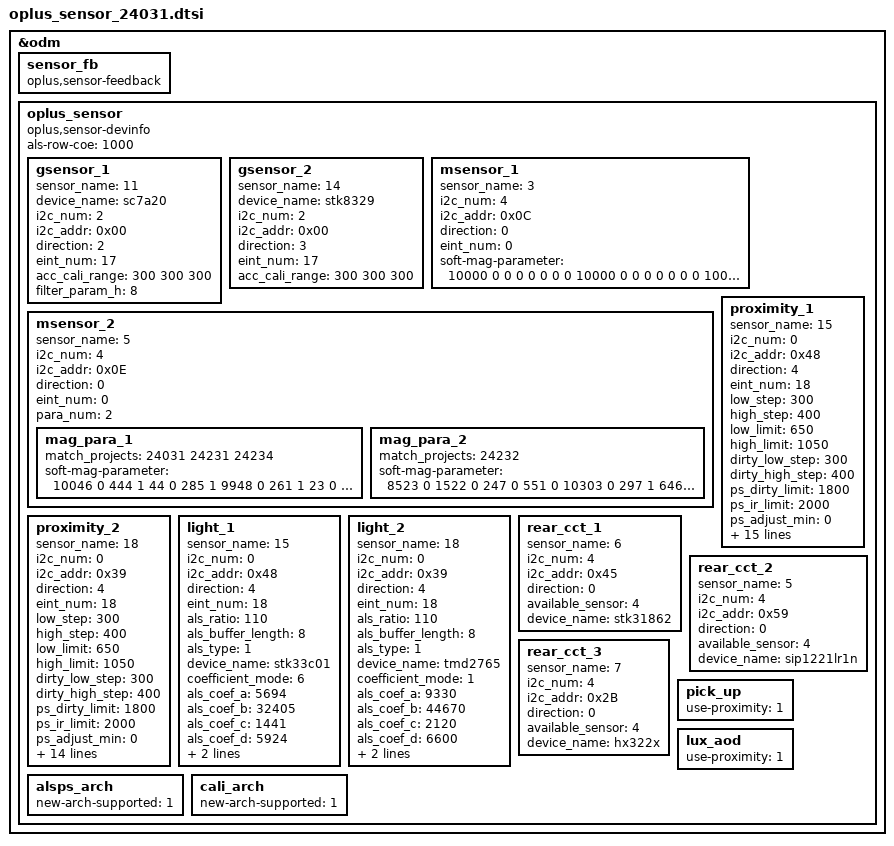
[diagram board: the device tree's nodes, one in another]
&odm {
	sensor_fb: sensor_fb {
		compatible = "oplus,sensor-feedback";
	};
	oplus_sensor:oplus_sensor {
		compatible = "oplus,sensor-devinfo";
		als-row-coe = <1000>;
		/* sensor start */
		/*
		enum {
			LIS3DH,
			LSM6DS3,
			BMI160,
			LIS2HH12,
			LSM6DSM,
			BMI2XY,
			LSM6DSO,
			ICM4X6XX,
			ICM4263X,
			ICM4N607,
			BMI22X,
			SC7A20,
			MC34X9,
			BMA4XY,
			STK8329,
			BMI3XY,
		};
		*/
		gsensor_1: gsensor_1 {
			status = "okay";
			sensor_name = <11>;//SC7A20
			device_name = "sc7a20";
			i2c_num = <2>;
			i2c_addr = <0x00>;
			direction = <2>;
			eint_num = <17>;
			acc_cali_range= <300 300 300>;
			filter_param_h = <8>;
		};
		gsensor_2: gsensor_2 {
			status = "okay";
			sensor_name = <14>;//STK8329
			device_name = "stk8329";
			i2c_num = <2>;
			i2c_addr = <0x00>;
			direction = <3>;
			eint_num = <17>;
			acc_cali_range= <300 300 300>;
		};
		/*
		enum {
			AKM09911,
			MMC3530,
			MMC5603,
			MXG4300,
			AKM09918,
		};
		*/
		msensor_1: msensor_1 {
			status = "okay";
			sensor_name = <3>;//MXG4300
			i2c_num = <4>;
			i2c_addr = <0x0C>;
			direction = <0>;
			eint_num = <0>;
			soft-mag-parameter = <10000 0 0 0 0 0 0 0 10000 0 0 0 0 0 0 0 10000 0>;
		};
		msensor_2: msensor_2 {
			status = "okay";
			sensor_name = <5>;//AKM09919
			i2c_num = <4>;
			i2c_addr = <0x0E>;
			direction = <0>;
			eint_num = <0>;
			para_num = <2>;
			mag_para_1 {
				match_projects = <24031 24231 24234>;
				soft-mag-parameter = <10046 0 444 1 44 0 285 1 9948 0 261 1 23 0 81 1 10662 0>;
			};
			mag_para_2 {
				match_projects = <24232>;
				soft-mag-parameter = <8523 0 1522 0 247 0 551 0 10303 0 297 1 646 0 993 1 10787 0>;
			};
		};
		/*
		enum {
			TMD2725,
			APSD9922,
			STK3335,
			STK3331,
			STK2232,
			TCS3701,
			STK32600,
			STK33502,
			MN78911,
			TCS3720,
			SIP3515,
			STK3329,
			LTR569,
			SIP3510,
		};
		*/
		proximity_1: proximity_1 {
			status = "okay";
			sensor_name = <15>; //stk33c01
			i2c_num = <0>;
			i2c_addr = <0x48>;
			direction = <4>;
			eint_num = <18>;
			low_step = <300>;
			high_step = <400>;
			low_limit = <650>;
			high_limit = <1050>;
			dirty_low_step = <300>;
			dirty_high_step = <400>;
			ps_dirty_limit = <1800>;
			ps_ir_limit = <2000>;
			ps_adjust_min = <0>;
			ps_adjust_max = <1850>;
			sampling_count = <5>;
			step_max = <400>;
			step_min = <100>;
			step_div = <2000>;
			anti_shake_delta = <70>;
			dynamic_cali_max = <2000>;
			raw2offset_radio = <1000>;
			offset_max = <60000>;
			offset_range_min = <0>;
			offset_range_max = <65534>;
			force_cali_limit = <2000>;
			cali_jitter_limit = <20>;
			cal_offset_margin = <3000>;
			sensor-reg = <0x01 0x43 0x03 0x3C>;
		};
		proximity_2: proximity_2 {
			status = "okay";
			sensor_name = <18>; //TMD2765
			i2c_num = <0>;
			i2c_addr = <0x39>;
			direction = <4>;
			eint_num = <18>;
			low_step = <300>;
			high_step = <400>;
			low_limit = <650>;
			high_limit = <1050>;
			dirty_low_step = <300>;
			dirty_high_step = <400>;
			ps_dirty_limit = <1800>;
			ps_ir_limit = <2000>;
			ps_adjust_min = <0>;
			ps_adjust_max = <1850>;
			sampling_count = <5>;
			step_max = <400>;
			step_min = <100>;
			step_div = <2000>;
			anti_shake_delta = <70>;
			dynamic_cali_max = <2000>;
			raw2offset_radio = <1000>;
			offset_max = <60000>;
			offset_range_min = <0>;
			offset_range_max = <65534>;
			force_cali_limit = <2000>;
			cali_jitter_limit = <20>;
			cal_offset_margin = <3000>;
		};
		light_1: light_1 {
			status = "okay";
			sensor_name = <15>; //stk33c01
			i2c_num = <0>;
			i2c_addr = <0x48>;
			direction = <4>;
			eint_num = <18>;
			als_ratio = <110>;
			als_buffer_length =<8>;
			als_type = <1>;//<1-normal;2-under screen;3-normal needed compensation>
			device_name = "stk33c01";
			coefficient_mode = <6>;
			als_coef_a = <5694>; //*100
			als_coef_b = <32405>; //*100
			als_coef_c = <1441>; //*100
			als_coef_d = <5924>; //*100
			als_coef_e = <2500>; //*100
			als_coef_ratio = <122>;
		};
		light_2: light_2 {
			status = "okay";
			sensor_name = <18>; //TMD2765
			i2c_num = <0>;
			i2c_addr = <0x39>;
			direction = <4>;
			eint_num = <18>;
			als_ratio = <110>;
			als_buffer_length =<8>;
			als_type = <1>;//<1-normal;2-under screen;3-normal needed compensation>
			device_name = "tmd2765";
			coefficient_mode = <1>;
			als_coef_a = <9330>; //*100
			als_coef_b = <44670>; //*100
			als_coef_c = <2120>; //*100
			als_coef_d = <6600>; //*100
			als_coef_e = <450>; //*100
			als_coef_ratio = <50>;
		};
		rear_cct_1: rear_cct_1 {
			status = "okay";
			sensor_name = <6>; //STK31862
			i2c_num = <4>;
			i2c_addr = <0x45>;
			direction = <0>;
			//eint_num = <18>;
			available_sensor = <4>; // bit 0: rear als, bit 1: rear cct, bit 2: rear flicker
			device_name = "stk31862";
		};
		rear_cct_2: rear_cct_2 {
			status = "okay";
			sensor_name = <5>; //SIP1221LR1N
			i2c_num = <4>;
			i2c_addr = <0x59>;
			direction = <0>;
			//eint_num = <18>;
			available_sensor = <4>; // bit 0: rear als, bit 1: rear cct, bit 2: rear flicker
			device_name = "sip1221lr1n";
		};
		rear_cct_3: rear_cct_3 {
			status = "okay";
			sensor_name = <7>; // HX322X
			i2c_num = <4>;
			i2c_addr = <0x2B>;
			direction = <0>;
			//eint_num = <18>;
			available_sensor = <4>; // bit 0: rear als, bit 1: rear cct, bit 2: rear flicker
			device_name = "hx322x";
		};
		pick_up: pick_up {
			status = "okay";
			use-proximity = <1>;
		};
		lux_aod: lux_aod {
			status = "okay";
			use-proximity = <1>;
		};
		alsps_arch: alsps_arch {
			status = "okay";
			new-arch-supported = <1>;
		};
		cali_arch: cali_arch {
			status = "okay";
			new-arch-supported = <1>;
		};
	};
/* sensor end */
};
